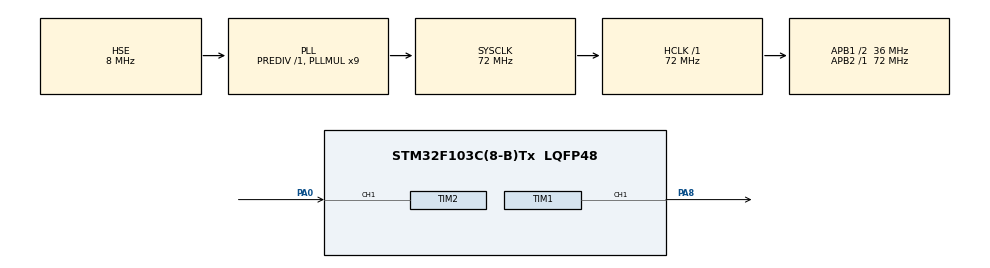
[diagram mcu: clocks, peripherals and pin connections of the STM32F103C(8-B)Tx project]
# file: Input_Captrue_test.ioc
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Mcu.Family=STM32F1
Mcu.Name=STM32F103C(8-B)Tx
Mcu.Package=LQFP48
NVIC.PriorityGroup=NVIC_PRIORITYGROUP_4
NVIC.TIM2_IRQn=true\:0\:0\:false\:false\:true\:true\:true\:true
PA0-WKUP.Signal=S_TIM2_CH1_ETR
PA13.Mode=Serial_Wire
PA13.Signal=SYS_JTMS-SWDIO
PA14.Mode=Serial_Wire
PA14.Signal=SYS_JTCK-SWCLK
PA8.Signal=S_TIM1_CH1
PD0-OSC_IN.Mode=HSE-External-Oscillator
PD0-OSC_IN.Signal=RCC_OSC_IN
PD1-OSC_OUT.Mode=HSE-External-Oscillator
PD1-OSC_OUT.Signal=RCC_OSC_OUT
ProjectManager.HeapSize=0x200
ProjectManager.StackSize=0x400
ProjectManager.TargetToolchain=MDK-ARM V5.32
RCC.AHBFreq_Value=72000000
RCC.APB1CLKDivider=RCC_HCLK_DIV2
RCC.APB1Freq_Value=36000000
RCC.APB1TimFreq_Value=72000000
RCC.APB2Freq_Value=72000000
RCC.APB2TimFreq_Value=72000000
RCC.HCLKFreq_Value=72000000
RCC.PLLMUL=RCC_PLL_MUL9
RCC.PLLSourceVirtual=RCC_PLLSOURCE_HSE
RCC.SYSCLKFreq_VALUE=72000000
RCC.SYSCLKSource=RCC_SYSCLKSOURCE_PLLCLK
RCC.USBFreq_Value=72000000
SH.S_TIM1_CH1.0=TIM1_CH1,PWM Generation1 CH1
SH.S_TIM2_CH1_ETR.0=TIM2_CH1,Input_Capture1_from_TI1
TIM1.Channel-PWM\ Generation1\ CH1=TIM_CHANNEL_1
TIM1.Period=100-1
TIM1.Prescaler=720-1
TIM1.Pulse-PWM\ Generation1\ CH1=50
TIM2.Channel-Input_Capture1_from_TI1=TIM_CHANNEL_1
TIM2.ICPolarity_CH1=TIM_INPUTCHANNELPOLARITY_RISING
TIM2.Period=65535
TIM2.Prescaler=7200-1
VP_TIM1_VS_ClockSourceINT.Mode=Internal
VP_TIM2_VS_ClockSourceINT.Mode=Internal
board=custom

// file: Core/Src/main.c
/* USER CODE BEGIN Header */
/**
  ******************************************************************************
  * @file           : main.c
  * @brief          : Main program body
  ******************************************************************************
  * @attention
  *
  * Copyright (c) 2026 STMicroelectronics.
  * All rights reserved.
  *
  * This software is licensed under terms that can be found in the LICENSE file
  * in the root directory of this software component.
  * If no LICENSE file comes with this software, it is provided AS-IS.
  *
  ******************************************************************************
  */
/**
  * 工程：Input_Captrue_Fre_Test —— 输入捕获测周期与频率（DAY16）
  * 硬件：TIM1_CH1 从 PA8 输出 1 kHz PWM，用跳线把 PA8 接到 PA0；TIM2_CH1（PA0）负责输入捕获
  * 时钟：HSE 8 MHz → PLL ×9 → 72 MHz；TIM1 挂 APB2（72 MHz，该总线预分频为 /1，走 ×1）
  *       TIM2 挂 APB1（36 MHz，预分频不为 1，定时器时钟 ×2 = 72 MHz）
  * 计数：TIM1：PSC = 720-1 → 计数 100 kHz；ARR = 100-1 → 输出 1 kHz；CCR = 50 → 占空比 50%
  *       TIM2：PSC = 7200-1 → 计数 10 kHz；ARR = 65535；两次上升沿之间的 CNT 差就是周期
  * 思路：只捕获上升沿，相邻两次上升沿的 CNT 差 = 一个周期的计数个数；频率 = 10 kHz ÷ 周期计数
  * 验证：算出的频率应接近 1000 Hz。注意这是用“名义计数频率”算的，晶振偏差测不出来，
  *       要判断绝对频率是否准确，得靠逻辑分析仪或示波器这类有独立时基的仪器
  */
/* USER CODE END Header */
#include "main.h"
#include "tim.h"
#include "gpio.h"

void SystemClock_Config(void);

int main(void)
{

  /* MCU Configuration--------------------------------------------------------*/

  /* Reset of all peripherals, Initializes the Flash interface and the Systick. */
  HAL_Init();

  /* Configure the system clock */
  SystemClock_Config();

  /* Initialize all configured peripherals */
  MX_GPIO_Init();
  MX_TIM2_Init();
  MX_TIM1_Init();
  /* USER CODE BEGIN 2 */
	HAL_TIM_IC_Start_IT(&htim2, TIM_CHANNEL_1);	// TIM2_CH1（PA0）启动输入捕获并允许捕获中断
	HAL_TIM_PWM_Start(&htim1, TIM_CHANNEL_1);	// TIM1_CH1（PA8）输出 1 kHz PWM，作为被测信号源
  /* USER CODE END 2 */

  /* Infinite loop */
  /* USER CODE BEGIN WHILE */
  while (1)
  {
    /* 主循环这里什么都不用做：捕获和频率计算全在 TIM2 的捕获中断里完成 */
    /* USER CODE END WHILE */

  }
}

void SystemClock_Config(void)
{
  RCC_OscInitTypeDef RCC_OscInitStruct = {0};
  RCC_ClkInitTypeDef RCC_ClkInitStruct = {0};

  /** Initializes the RCC Oscillators according to the specified parameters
  * in the RCC_OscInitTypeDef structure.
  */
  RCC_OscInitStruct.OscillatorType = RCC_OSCILLATORTYPE_HSE;
  RCC_OscInitStruct.HSEState = RCC_HSE_ON;
  RCC_OscInitStruct.HSEPredivValue = RCC_HSE_PREDIV_DIV1;
  RCC_OscInitStruct.HSIState = RCC_HSI_ON;
  RCC_OscInitStruct.PLL.PLLState = RCC_PLL_ON;
  RCC_OscInitStruct.PLL.PLLSource = RCC_PLLSOURCE_HSE;
  RCC_OscInitStruct.PLL.PLLMUL = RCC_PLL_MUL9;
  if (HAL_RCC_OscConfig(&RCC_OscInitStruct) != HAL_OK)
  {
    Error_Handler();
  }

  /** Initializes the CPU, AHB and APB buses clocks
  */
  RCC_ClkInitStruct.ClockType = RCC_CLOCKTYPE_HCLK|RCC_CLOCKTYPE_SYSCLK
                              |RCC_CLOCKTYPE_PCLK1|RCC_CLOCKTYPE_PCLK2;
  RCC_ClkInitStruct.SYSCLKSource = RCC_SYSCLKSOURCE_PLLCLK;
  RCC_ClkInitStruct.AHBCLKDivider = RCC_SYSCLK_DIV1;
  RCC_ClkInitStruct.APB1CLKDivider = RCC_HCLK_DIV2;
  RCC_ClkInitStruct.APB2CLKDivider = RCC_HCLK_DIV1;

  if (HAL_RCC_ClockConfig(&RCC_ClkInitStruct, FLASH_LATENCY_2) != HAL_OK)
  {
    Error_Handler();
  }
}

void Error_Handler(void)
{
  __disable_irq();
  while (1)
  {
  }
}
